# GD32E511_512 register map
File version: 1.0
CPU: CM33 r0p4, little endian, MPU, FPU, 4 interrupt priority bits
Registers are 32-bit, read-write, reset 0x0 unless marked. A register's access mark holds for its fields unless they carry their own. Offsets are from the block's base; [hi:lo] are bit positions; {n}, {i} and the like mark numbered series; 'fields as' and 'values as' point back to an identical list.

## ADC0 — Analog to digital converter
Base 0x40012400
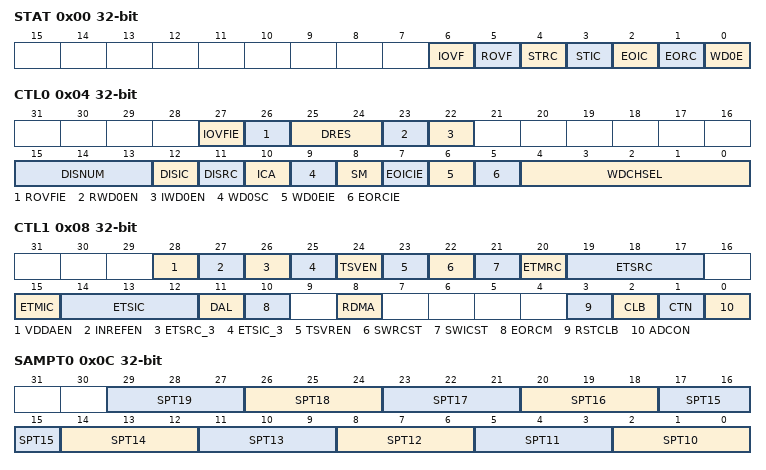
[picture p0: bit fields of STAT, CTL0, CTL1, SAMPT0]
0x00 STAT — Status register
  [6] IOVF — Inserted data register overflow
  [5] ROVF — Routine data register overflow
  [4] STRC — Start flag of routine sequence
  [3] STIC — Start flag of inserted sequence
  [2] EOIC — End flag of inserted sequence conversion
  [1] EORC — End flag of routine sequence conversion
  [0] WD0E — Analog watchdog 0 event flag
0x04 CTL0 — Control register 0
  [27] IOVFIE — Interrupt enable for IOVF
  [26] ROVFIE — Interrupt enable for ROVF
  [25:24] DRES — ADC resolution
  [23] RWD0EN — Routine sequence analog watchdog 0 enable
  [22] IWD0EN — Inserted sequence analog watchdog 0 enable
  [15:13] DISNUM — Number of conversions in discontinuous mode
  [12] DISIC — Discontinuous mode on inserted sequence
  [11] DISRC — Discontinuous mode on routine sequence
  [10] ICA — Inserted sequence convert automatically
  [9] WD0SC — When in scan mode, analog watchdog 0 is effective on a single channel
  [8] SM — Scan mode
  [7] EOICIE — Interrupt enable for EOIC
  [6] WD0EIE — Interrupt enable for WD0E
  [5] EORCIE — Interrupt enable for EORC
  [4:0] WDCHSEL — Analog watchdog channel select
0x08 CTL1 — Control register 1
  [28] VDDAEN — This bit can be set or cleared by software in ADC0.
  [27] INREFEN — This bit can be set or cleared by software in ADC0.
  [26] ETSRC_3 — External trigger select for routine sequence. Refer to ETSRC[2:0].
  [25] ETSIC_3 — External trigger select for inserted sequence. Refer to ETSIC[2:0].
  [24] TSVEN — This bit can be set or cleared by software in ADC0.
  [23] TSVREN — This bit can be set or cleared by software in ADC0.
  [22] SWRCST — Software start conversion of routine sequence.
  [21] SWICST — Software start on inserted sequence.
  [20] ETMRC — External trigger mode for routine sequence
  [19:17] ETSRC — External trigger select for routine sequence
  [15] ETMIC — External trigger mode for inserted sequence
  [14:12] ETSIC — External trigger select for inserted sequence
  [11] DAL — Data alignment
  [10] EORCM — End of conversion mode
  [8] RDMA — DMA request enable for routine sequence.
  [3] RSTCLB — Reset calibration
  [2] CLB — ADC calibration
  [1] CTN — Continuous mode
  [0] ADCON
0x0C SAMPT0 — Sample time register 0
  [3n-28:3n-30] SPT{n} (n=10..19) — Refer to SPT0[2:0] description
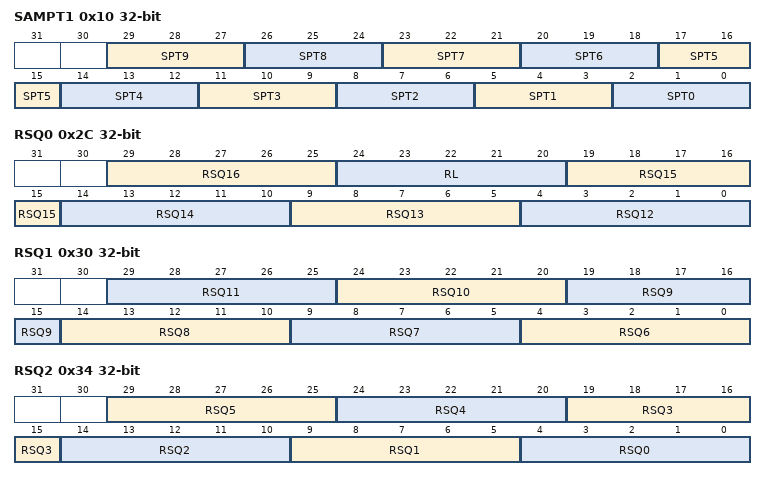
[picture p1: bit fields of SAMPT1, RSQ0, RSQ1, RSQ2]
0x10 SAMPT1 — Sample time register 1
  [3n+2:3n] SPT{n} (n=1..9) — Refer to SPT0[2:0] description
  [2:0] SPT0 — Channel sampling time
{0x14+4i} IOFF{i} (i=0..3) — Inserted channel data offset register {i}
  [11:0] IOFF — Data offset for inserted channel x.
0x24 WD0HT reset 0xFFFFF — Watchdog 0 high threshold register
  [19:0] WD0HT — High threshold for analog watchdog 0
0x28 WD0LT — Watchdog 0 low threshold register
  [19:0] WD0LT — Low threshold for analog watchdog 0
0x2C RSQ0 — Routine sequence register 0
  [29:25] RSQ16 — Refer to RSQ0[4:0] description.
  [24:20] RL — Routine channel length
  [19:15] RSQ15 — Refer to RSQ0[4:0] description.
  [14:10] RSQ14 — Refer to RSQ0[4:0] description.
  [9:5] RSQ13 — Refer to RSQ0[4:0] description.
  [4:0] RSQ12 — Refer to RSQ0[4:0] description
0x30 RSQ1 — Routine sequence register 1
  [5n-26:5n-30] RSQ{n} (n=6..11) — Refer to RSQ0[4:0] description
0x34 RSQ2 — Routine sequence register 2
  [5n+4:5n] RSQ{n} (n=1..5) — Refer to RSQ0[4:0] description
  [4:0] RSQ0 — The channel number (0~24 for ADC0, 0~19 for ADC1) is written to these bits to select a channel as the nth conversion in the routine sequence.
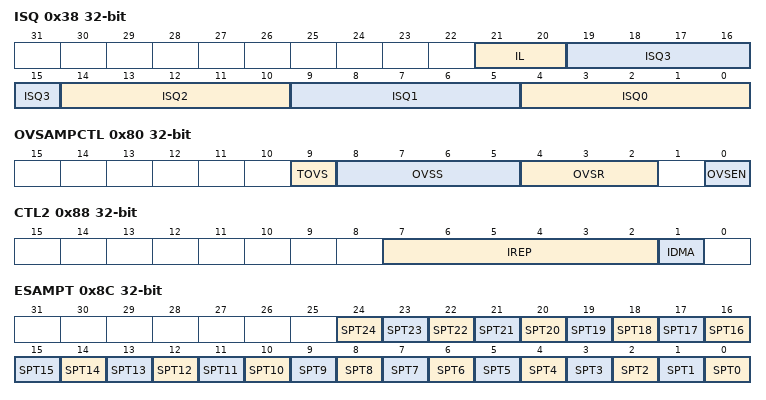
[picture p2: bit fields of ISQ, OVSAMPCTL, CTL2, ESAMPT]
0x38 ISQ — Inserted sequence register
  [21:20] IL — Inserted channel length.
  [19:15] ISQ3 — Refer to ISQ0[4:0] description
  [14:10] ISQ2 — Refer to ISQ0[4:0] description
  [9:5] ISQ1 — Refer to ISQ0[4:0] description
  [4:0] ISQ0 — The channel number (0~24 for ADC0, 0~19 for ADC1) is written to these bits to select a channel as the nth conversion in the inserted sequence.
{0x3C+4i} LDATA{i} ro (i=0..3) — Latch data register {i}
  [15:0] LDATAn — Inserted or routine number n conversion data.
0x4C RDATA ro — Routine data register
  [15:0] RDATA — Routine channel data
0x80 OVSAMPCTL — Oversampling control register
  [9] TOVS — Triggered Oversampling
  [8:5] OVSS — Oversampling shift
  [4:2] OVSR — Oversampling ratio
  [0] OVSEN — Oversampling enable
0x88 CTL2 — Control register 2
  [7:2] IREP — Inserted sequence repeat times.
  [1] IDMA — DMA request enable for inserted sequence
0x8C ESAMPT — Expand sample time register
  [n] SPT{n} (n=0..24) — Channel sampling time. Refer to SPT{n}[2:0].
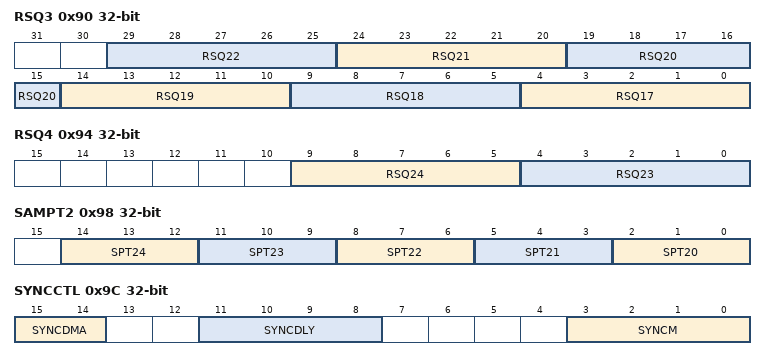
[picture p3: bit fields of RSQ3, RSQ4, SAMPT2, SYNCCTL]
0x90 RSQ3 — Routine sequence register 3
  [5n-81:5n-85] RSQ{n} (n=17..22) — Refer to RSQ0[4:0] description
0x94 RSQ4 — Routine sequence register 4
  [9:5] RSQ24 — Refer to RSQ0[4:0] description
  [4:0] RSQ23 — Refer to RSQ0[4:0] description
0x98 SAMPT2 — Sample time register 2
  [3n-58:3n-60] SPT{n} (n=20..24) — Refer to SPT0[2:0] description
0x9C SYNCCTL — Sync control register
  [15:14] SYNCDMA — ADC sync DMA mode selection
  [11:8] SYNCDLY — ADC sync delay
  [3:0] SYNCM — ADC sync mode
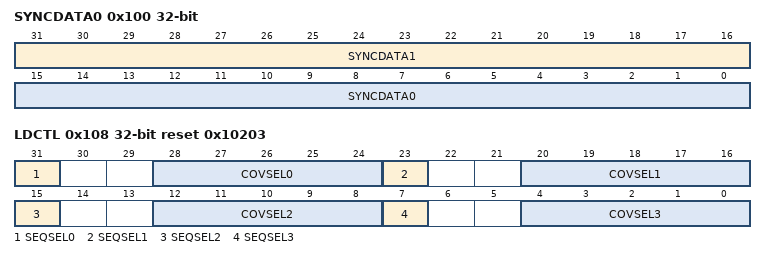
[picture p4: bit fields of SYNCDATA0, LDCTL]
0x100 SYNCDATA0 ro — Sync routine data register
  [31:16] SYNCDATA1 — When SYNCDMA[1:0]=2'b10, these bits are routine data1(slave adc routine data) in ADC sync mode.
  [15:0] SYNCDATA0 — When SYNCDMA[1:0]=2'b10, these bits are routine data0 (master adc routine data) in ADC sync mode.
0x104 IDATA ro — Inserted data register
  [15:0] IDATA — Inserted channel data
0x108 LDCTL reset 0x10203 — Latch data control registe
  [31] SEQSEL0 — The ADC_LDATA0 register sequence source selection
  [28:24] COVSEL0 — The ADC_LDATA0 register conversion source selection
  [23] SEQSEL1 — Refer to SEQSEL0 description.
  [20:16] COVSEL1 — Refer to COVSEL0[4:0] description.
  [15] SEQSEL2 — Refer to SEQSEL0 description.
  [12:8] COVSEL2 — Refer to COVSEL0[4:0] description.
  [7] SEQSEL3 — Refer to SEQSEL0 description.
  [4:0] COVSEL3 — Refer to COVSEL0[4:0] description.

## ADC1 — Analog to digital converter
Base 0x40012800
Registers as ADC0, without RSQ4, SAMPT2, SYNCCTL, SYNCDATA0; these are added or differ:
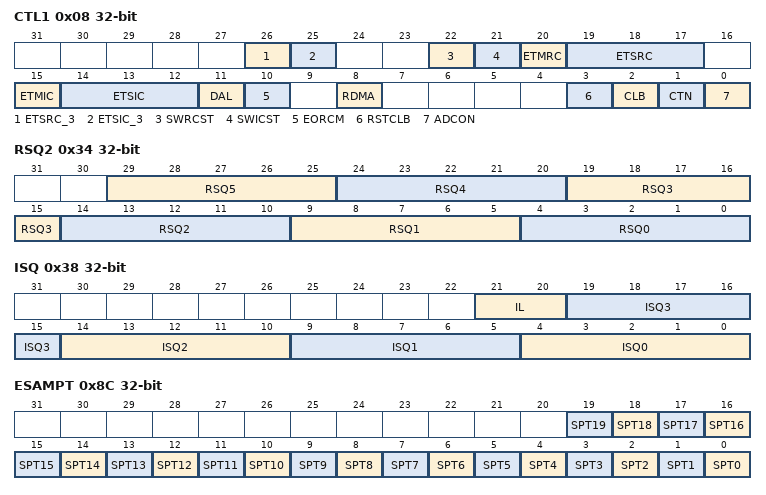
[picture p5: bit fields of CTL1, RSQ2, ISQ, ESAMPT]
0x08 CTL1 — Control register 1
  [26] ETSRC_3 — External trigger select for routine sequence. Refer to ETSRC[2:0].
  [25] ETSIC_3 — External trigger select for inserted sequence. Refer to ETSIC[2:0].
  [22] SWRCST — Software start conversion of routine sequence.
  [21] SWICST — Software start on inserted sequence.
  [20] ETMRC — External trigger mode for routine sequence
  [19:17] ETSRC — External trigger select for routine sequence
  [15] ETMIC — External trigger mode for inserted sequence
  [14:12] ETSIC — External trigger select for inserted sequence
  [11] DAL — Data alignment
  [10] EORCM — End of conversion mode
  [8] RDMA — DMA request enable for routine sequence.
  [3] RSTCLB — Reset calibration
  [2] CLB — ADC calibration
  [1] CTN — Continuous mode
  [0] ADCON
0x34 RSQ2 — Routine sequence register 2
  fields as ADC0.RSQ2
0x38 ISQ — Inserted sequence register
  fields as ADC0.ISQ
0x8C ESAMPT — Expand sample time register
  [n] SPT{n} (n=0..19) — Channel sampling time. Refer to SPT{n}[2:0].
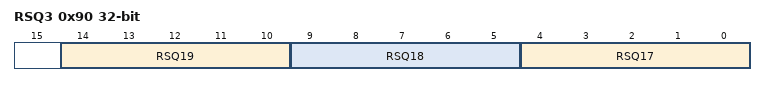
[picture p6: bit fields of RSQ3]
0x90 RSQ3 — Routine sequence register 3
  [14:10] RSQ19 — Refer to RSQ0[4:0] description
  [9:5] RSQ18 — Refer to RSQ0[4:0] description
  [4:0] RSQ17 — Refer to RSQ0[4:0] description
